# ATmega1284P register map
Vendor: Atmel; Series: ATmega128; File version: 1.1
CPU: other r0p0, little endian, no MPU, no FPU, VTOR, 4 interrupt priority bits
Registers are 8-bit, read-write, reset 0x0 unless marked. A register's access mark holds for its fields unless they carry their own. Offsets are from the block's base; [hi:lo] are bit positions; {n}, {i} and the like mark numbered series.

## TWI — Two Wire Serial Interface
Base 0x000000B8
0x00 TWBR — TWI Bit Rate register
  [7:0] TWBR — TWI Bit Rate bits
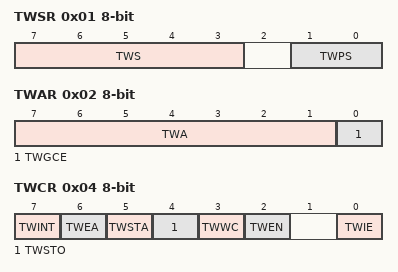
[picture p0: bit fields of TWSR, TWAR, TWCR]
0x01 TWSR — TWI Status Register
  [7:3] TWS ro — TWI Status
  [1:0] TWPS — TWI Prescaler
    0=PRESCALER_1 (Prescaler Value 1); 1=PRESCALER_4 (Prescaler Value 4); 2=PRESCALER_16 (Prescaler Value 16); 3=PRESCALER_64 (Prescaler Value 64)
0x02 TWAR — TWI (Slave) Address register
  [7:1] TWA — TWI (Slave) Address register Bits
  [0] TWGCE — TWI General Call Recognition Enable Bit
0x03 TWDR — TWI Data register
  [7:0] TWD — TWI Data bits
0x04 TWCR — TWI Control Register
  [7] TWINT — TWI Interrupt Flag
  [6] TWEA — TWI Enable Acknowledge Bit
  [5] TWSTA — TWI Start Condition Bit
  [4] TWSTO — TWI Stop Condition Bit
  [3] TWWC ro — TWI Write Collition Flag
  [2] TWEN — TWI Enable Bit
  [0] TWIE — TWI Interrupt Enable
0x05 TWAMR — TWI (Slave) Address Mask Register
  [7:1] TWAM — TWI (Slave) Address Mask Bits

## USART0 — USART
Base 0x000000C0
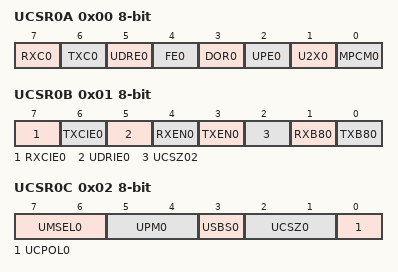
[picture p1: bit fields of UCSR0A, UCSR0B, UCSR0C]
0x00 UCSR0A — USART Control and Status Register A
  [7] RXC0 ro — USART Receive Complete
  [6] TXC0 — USART Transmit Complete
  [5] UDRE0 ro — USART Data Register Empty
  [4] FE0 ro — Framing Error
  [3] DOR0 ro — Data overRun
  [2] UPE0 ro — Parity Error
  [1] U2X0 — Double the USART transmission speed
  [0] MPCM0 — Multi-processor Communication Mode
0x01 UCSR0B — USART Control and Status Register B
  [7] RXCIE0 — RX Complete Interrupt Enable
  [6] TXCIE0 — TX Complete Interrupt Enable
  [5] UDRIE0 — USART Data register Empty Interrupt Enable
  [4] RXEN0 — Receiver Enable
  [3] TXEN0 — Transmitter Enable
  [2] UCSZ02 — Character Size
  [1] RXB80 ro — Receive Data Bit 8
  [0] TXB80 — Transmit Data Bit 8
0x02 UCSR0C — USART Control and Status Register C
  [7:6] UMSEL0 — USART Mode Select
    0=USART_ASYNC (Asynchronous USART); 1=USART_SYNC (Synchronous USART); 3=SPI_MASTER (Master SPI (MSPIM))
  [5:4] UPM0 — Parity Mode Bits
    0=DISABLED; 2=PARITY_EVEN (Enabled, Even Parity); 3=PARITY_ODD (Enabled, Odd Parity)
  [3] USBS0 — Stop Bit Select
    0=STOP1 (1-bit); 1=STOP2 (2-bit)
  [2:1] UCSZ0 — Character Size
    {v}=CHR{v+5} (Character Size: {v+5} bit) (v=0..3)
  [0] UCPOL0 — Clock Polarity
    0=RISING_EDGE (Transmit on Rising XCKn Edge, Receive on Falling XCKn Edge); 1=FALLING_EDGE (Transmit on Falling XCKn Edge, Receive on Rising XCKn Edge)
0x04 UBRR0 16-bit (reset mask 0xFF) — USART Baud Rate Register Bytes
  [11:0] UBRR0 — USART Baud Rate Register
0x06 UDR0 — USART I/O Data Register
  [7:0] UDR0 — USART I/O Data bits

## USART1 — USART
Base 0x000000C8
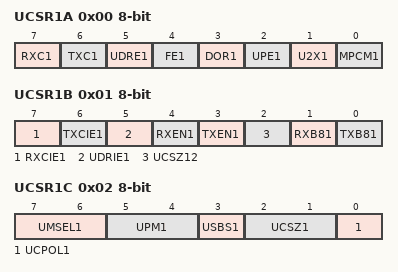
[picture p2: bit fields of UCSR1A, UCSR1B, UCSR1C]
0x00 UCSR1A — USART Control and Status Register A
  [7] RXC1 ro — USART Receive Complete
  [6] TXC1 — USART Transmit Complete
  [5] UDRE1 ro — USART Data Register Empty
  [4] FE1 ro — Framing Error
  [3] DOR1 ro — Data overRun
  [2] UPE1 ro — Parity Error
  [1] U2X1 — Double the USART transmission speed
  [0] MPCM1 — Multi-processor Communication Mode
0x01 UCSR1B — USART Control and Status Register B
  [7] RXCIE1 — RX Complete Interrupt Enable
  [6] TXCIE1 — TX Complete Interrupt Enable
  [5] UDRIE1 — USART Data register Empty Interrupt Enable
  [4] RXEN1 — Receiver Enable
  [3] TXEN1 — Transmitter Enable
  [2] UCSZ12 — Character Size
  [1] RXB81 ro — Receive Data Bit 8
  [0] TXB81 — Transmit Data Bit 8
0x02 UCSR1C — USART Control and Status Register C
  [7:6] UMSEL1 — USART Mode Select
    0=USART_ASYNC (Asynchronous USART); 1=USART_SYNC (Synchronous USART); 3=SPI_MASTER (Master SPI (MSPIM))
  [5:4] UPM1 — Parity Mode Bits
    0=DISABLED; 2=PARITY_EVEN (Enabled, Even Parity); 3=PARITY_ODD (Enabled, Odd Parity)
  [3] USBS1 — Stop Bit Select
    0=STOP1 (1-bit); 1=STOP2 (2-bit)
  [2:1] UCSZ1 — Character Size
    {v}=CHR{v+5} (Character Size: {v+5} bit) (v=0..3)
  [0] UCPOL1 — Clock Polarity
    0=RISING_EDGE (Transmit on Rising XCKn Edge, Receive on Falling XCKn Edge); 1=FALLING_EDGE (Transmit on Falling XCKn Edge, Receive on Rising XCKn Edge)
0x04 UBRR1 16-bit (reset mask 0xFF) — USART Baud Rate Register Bytes
  [11:0] UBRR1 — USART Baud Rate Register
0x06 UDR1 — USART I/O Data Register
  [7:0] UDR1 — USART I/O Data bits

## WDT — Watchdog Timer
Base 0x00000060
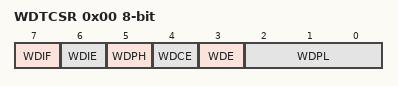
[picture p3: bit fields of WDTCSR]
0x00 WDTCSR — Watchdog Timer Control Register
  [7] WDIF — Watchdog Timeout Interrupt Flag
  [6] WDIE — Watchdog Timeout Interrupt Enable
  [5] WDPH — Watchdog Timer Prescaler - High Bit
  [4] WDCE — Watchdog Change Enable
  [3] WDE — Watch Dog Enable
  [2:0] WDPL — Watchdog Timer Prescaler - Low Bits
    0=CYCLES_2K_512K (- 2048 cycles, ~16ms/512K (524288) cycles, ~4s if WDPH is set); 1=CYCLES_4K_1024K (- 4096 cycles, ~32ms/1024K (1048576) cycles, ~8s if WDPH is set); 2=CYCLES_8K (- 8192 cycles, ~64ms); 3=CYCLES_16K (- 16K (16384) cycles, ~0.125s); 4=CYCLES_32K (- 32K (32768) cycles, ~0.25s); 5=CYCLES_64K (- 64K (65536) cycles, ~0.5s); 6=CYCLES_128K (- 128K (131072) cycles, ~1s); 7=CYCLES_256K (- 256K (262144) cycles, ~2s)
